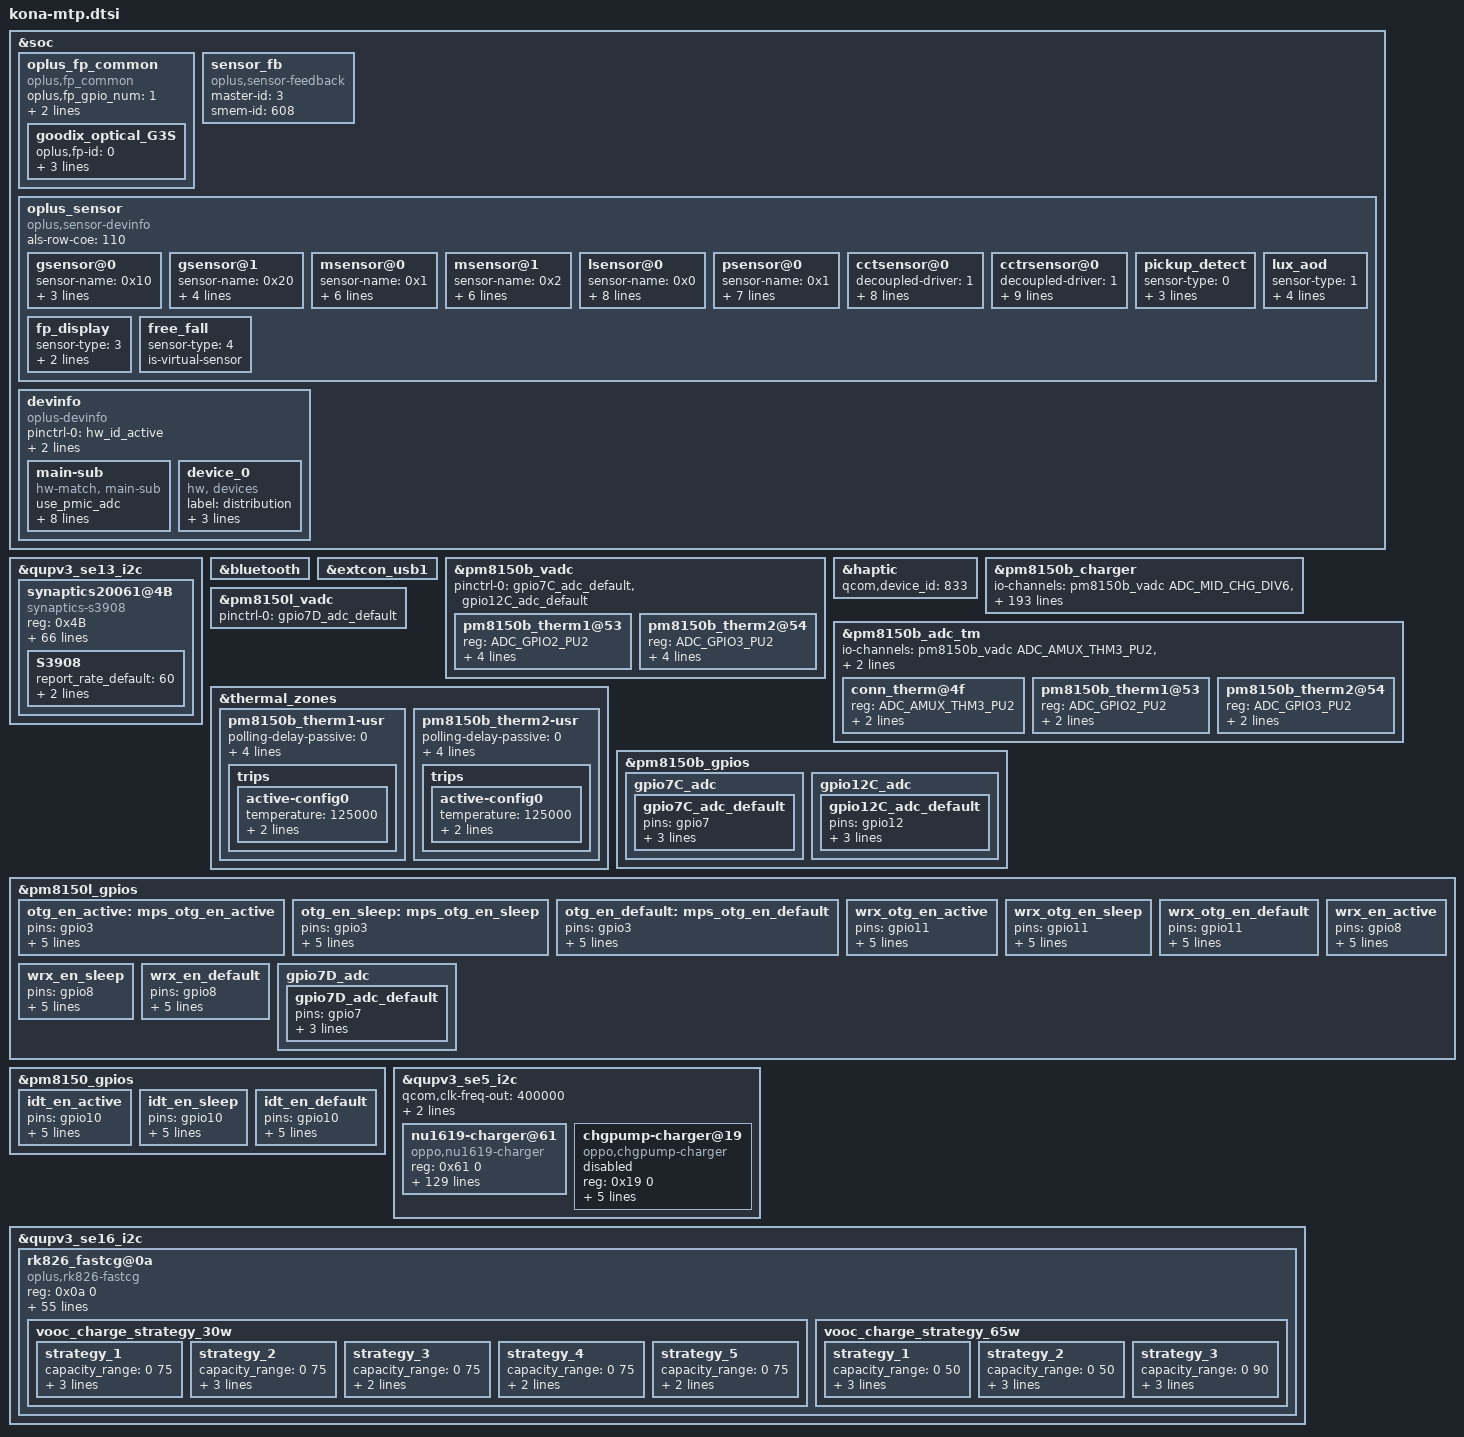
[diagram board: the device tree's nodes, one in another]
#include "kona-audio-overlay.dtsi"
#include "kona-camera-sensor-mtp-20061.dtsi"
#include "kona-pmic-overlay.dtsi"
#include "kona-sde-display.dtsi"

&soc {
	oplus_fp_common {
		compatible = "oplus,fp_common";
		oplus,fp_gpio_num = <1>; /* the gpio number of fingerprint id used */
		oplus,fp_gpio_0 = <&tlmm 9 0x0>;
				pinctrl-names = "default";
		pinctrl-0 = <&gpio_id2_default>;
		goodix_optical_G3S {
			oplus,fp-id = <0>; /* fp id mapping table */
			vendor-chip = <11>; /* please refer to the struct fp_vendor_t in oplus_fp_commmon.n */
			eng-menu = "-1,-1"; /* represents SNR, inclination test item in engineer menu, and 0/1 means off/on */
			chip-name = "G_OPTICAL_G3S";  /* /proc/fp_id, will be displayed in engineer menu  */
		};
	};

	/*enum sensor_id { ACCEL,GYRO,MAG,LIGHT,PROXIMITY,SAR,CT,BAROMETER,SENSORS_NUM};*/
    sensor_fb: sensor_fb {
        compatible = "oplus,sensor-feedback";
        master-id  = <3>;
        smem-id    = <608>;
    };

	oplus_sensor {
		compatible = "oplus,sensor-devinfo";
		als-row-coe = <110>;
		/*enum {LSM6DSM = 0x01, BMI160 = 0x02, LSM6DS3 = 0x04};*/
		gsensor@0 {
			sensor-name = <0x10>;//LSM6DSO
			sensor-direction = <7>;
			sensor-index = <0>;//source num
			sensor-type = <0>;//ACCEL
		};
		gsensor@1 {
			sensor-name = <0x20>;//ICM4X6XX
			sensor-direction = <7>;
			sensor-index = <1>;//source num
			sensor-type = <0>;//ACCEL
			use-sois = <1>;   //Use for TDK-sensor, <1>:S-OIS,  <0>:tele ois ic
		};
		/* enum {AKM0991X = 0x01, MMC5603 = 0x02};*/
		msensor@0 {
			sensor-name = <0x1>;//AKM0991X
			sensor-direction = <2>;
			sensor-index = <0>;
			sensor-type = <2>;//MAG
			parameter-number= <18>;
			//sensor-parameter = <2>;//0-useless;other- to differ special parameter
			soft-mag-parameter = <10000 0 0 0 0 0 0 0 10000 0 0 0 0 0 0 0 10000 0>;//e00 sign e01 sign ...
		};
		msensor@1 {
			sensor-name = <0x2>;//MMC5603
			sensor-direction = <1>;
			sensor-index = <1>;
			sensor-type = <2>;//MAG
			parameter-number= <18>;
			soft-mag-parameter = <9912 0 1306 0 174 0 914 0 9825 0 444 1 336 0 482 1 11899 0>;//e00 sign e01 sign ...

		};
		/*enum {STK3A5X=0x01,TCS3701=0x02,TCS3408=0x04};*/
		lsensor@0 {
			sensor-name = <0x0>;//TCS3408
			sensor-index = <0>;
			sensor-type = <3>;//LIGHT
			als-type = <1>;//<1-normal;2-under screen;3-normal needed compensation>
			is-unit-device = <0>;//<1-alsps unit device;0-separate device>
			is-als-dri = <0>;//<0-polling 1-irq>
			als-factor = <110>;
			is_als_initialed = <0>;
			als_buffer_length = <10>;
		};
		psensor@0 {
			sensor-name = <0x1>;//STK33502
			sensor-index = <0>;
			sensor-type = <4>;//PROXIMITY
			bus-number = <5>;
			irq-number = <129>;
			ps-type = <1>;
			parameter-number = <4>;
			sensor-reg = <0x01 0x31
					0xDB 0x00>;

		};
		/* enum {tcs3408 = 0x01  stk37600 = 0x02} */
		cctsensor@0 {
			decoupled-driver = <1>; //0 - tcs3408 driver; 1 - oplus_cct driver
			sensor-name = <0x1>; //tcs3408
			sensor-index = <0>;
			sensor-type = <6>; //CCT
			bus-number = <5>;
			publish-sensors = <0x7>; //bit[0] - als, bit[1] - rgb, bit[2] - flicker
			is-ch-dri = <0>;
			timer-size = <25>; //ms
			fac-cali-sensor = <0x2>; //0x1 - als, 0x2 - rgb, 0x4, flicker
		};
		cctrsensor@0 {
			decoupled-driver = <1>; //0 - tcs3408 driver; 1 - oplus_cct driver
			sensor-name = <0x1>; //tcs3408
			sensor-index = <0>;
			sensor-type = <7>; //CCT_REAR
			bus-number = <4>;
			publish-sensors = <0x7>; //bit[0] - als, bit[1] - rgb, bit[2] - flicker
			is-ch-dri = <0>;
			timer-size = <25>; //ms
			fac-cali-sensor = <0x2>; //0x1 - als, 0x2 - rgb, 0x4, flicker
			first-again = <32>;
		};
		/*virtual sensor
		enum sensor_algo_id {
			PICKUP_DETECT,
			LUX_AOD,
			TP_GESTURE,
			FP_DISPLAY,
			FREE_FALL,
			CAMERA_PROTECT,
			SENSOR_ALGO_NUM
		}*/
		pickup_detect {
			sensor-type = <0>;//PICKUP_DETECT
			is-virtual-sensor;
			is-need-prox = <1>;//0 - disable; 1 - enable
			prox-type = <0>;//prox_type: 0 - proximity; 1 - proximity_fake
		};
		lux_aod {
			sensor-type = <1>; //LUX_AOD
			is-virtual-sensor;
			thrd-low = <12>;
			thrd-high = <50>;
			als-type = <0>; // 0 - ambient_light; 1 - wise_light
		};
		fp_display {
			sensor-type = <3>;//FP_DISPLAY
			is-virtual-sensor;
			prox-type = <0>; //  0 - proximity; 1 - proximity_fake
		};
		free_fall {
			sensor-type = <4>;//FREE_FALL
			is-virtual-sensor;
		};
	};


	devinfo {
		compatible = "oplus-devinfo";

		pinctrl-names = "active", "sleep";
		pinctrl-0 = <&hw_id_active>;
		pinctrl-1 = <&hw_id_sleep>;

		io-channels= <&pm8150l_vadc ADC_GPIO1>;
		io-channel-names= "vph_pwr_voltage_sub";

		main-sub {
			compatible = "hw-match, main-sub";
			use_pmic_adc;
			adc_ranges = <0 80
						81 180
						181 300
						301 420
						421 550
						551 650
						651 760
						761 850
						851 950
						951 1050
						1051 1150
						1151 1300>;
			aboard-patterns = <1 1 1 1 1 1 1 1 1 1 1 1 1 1 1 1>;

			/*main board*/
			match-projects = <20061 20062 20061 20062 20061 20062
			                 20061 20062 20061 20062 20061 20062 20061 20062 20061 20062>;

			/*rf type*/
			rf_match_support;
			rf-patterns = <0 0 1 1 2 2 3 3 4 4 5 5 6 6 7 7>;
		};

		device_0 {
			compatible = "hw, devices";
			label = "distribution";
			hw-id0 = <&pm8150_gpios 1 0>;
			hw-combs = <1 0>;
			hw-names = "Standard", "Pro";
		};
	};
};

&qupv3_se13_i2c {
	status = "okay";

	synaptics20061@4B {
		compatible = "synaptics-s3908";
		reg = <0x4B>;
		chip-name = "S3908";

		/* Interrupt && Irq-gpio */
		interrupt-parent = <&tlmm>;
		interrupts = <39 0x2008>;

		/* Power Config */
		vdd_2v8-supply = <&pm8150_l13>;
		vcc_1v8-supply = <&pm8150a_l1>;
		vdd_2v8_volt = <3008000>;

		/* Other HW Resource */
		irq-gpio = <&tlmm 39 0x2008>;
		reset-gpio = <&tlmm 38 0x1>;
		pinctrl-names = "default";
		pinctrl-0 = <&ts_int_active &ts_reset_active>;

		vid_len = <0>;
		tp_type = <8>;
		// type of tp_dev ,TP-SAMSUNG = 8;
		platform_support_project = <20061 20062>;
		platform_support_project_dir = <20061 20061>;
		platform_support_project_commandline = "mdss_dsi_oplus20061_samsung_1440_3216", "mdss_dsi_oplus20061_samsung_1440_3216";

		touchpanel,max-num-support = <10>;
		touchpanel,tx-rx-num = <17 38>;
		touchpanel,panel-coords = <5760 12864>;
		touchpanel,display-coords = <1440 3216>;
		touchpanel,touchmajor-limit = <128 216>;
		touchpanel,int-mode = <1>; /*0: interrupt and disable, 1:interrupt and not disable*/
		touchpanel,curved-size = <45>;
		touchpanel,smooth-level = <0 2 3 4 10 13>;
		touchpanel,smooth-level-charging = <0 6 8 10 13 15>;
		touchpanel,sensitive-level = <0 88 70 64 45 20>;
		touchpanel,single-optimized-time = <8>;

		/*edge inhibition 3.0 Feature porting start*/
		prevention,curved_screen_V2;
		prevention,updelay_time_ms = <30>;
		prevention,makeup_cnt_weight = <4 1 2 2 2>;
		prevention,large_corner_range = <600 1400>;
		prevention,large_corner_judge_condition = <500 100 600 4 4>;
		prevention,trx_reject_condition = <8 7 7>;
		prevention,trx_strict_reject_condition = <8 5 5>;
		prevention,large_judge_time_ms = <500 50 40>;
		prevention,large_exit_condition = <8 8 2>;
		prevention,single_channel_width = <160 160>;
		prevention,normal_tap_condition = <10 300>;
		prevention,long_edge_condition = <230 90 180 80>;
		prevention,long_strict_edge_condition = <160 60>;
		prevention,long_fingerhold_condition = <50 6 4 4>;
		prevention,short_edge_condition = <200 90 180 80>;
		prevention,short_strict_edge_condition = <160 60>;
		prevention,large_strict_exit_condition = <2 2>;
		prevention,top_corner_config = <280 800 240>;
		prevention,edge_swipe_config = <150 400>;
                prevention,grip_disable_level = <6>;
		/*edg inhibition 3.0 Feature porting end*/

		/* SW Support Feature Control */
		health_monitor_v2_support;
		black_gesture_support;
		//fw_edge_limit_support;
		kernel_grip_support;
		pressure_report_support;
		charger_pump_support;
		game_switch_support;
		smart_gesture_support;
		fw_update_app_support;
		fingerprint_underscreen_support;
		freq_hop_simulate_support;
		report_flow_unlock_support;
		screenoff_fingerprint_info_support;
		irq_need_dev_resume_ok;
		black_gesture_indep_support;
		lcd_tp_refresh_support;
		/*
		 *Virtual Key Config:
		 *1:touchpanel,button-type: <virtualkey_type  supportted_button-map>
		 *virtualkey_type:
		 *Type 1: using board_properties
		 *Type 2: using same IC (button zone&& touch zone are seprate)
		 *Type 3: using diffrent IC (button zone&& touch zone are seprate)
		 *Type 4: No need of virtual key process
		 *supportted_button-map:select|menu|home|back
		 *
		 *2:touchpanel,button-map
		 *type (X1,Y1)(X2,Y2)(X3,Y3)(Width_X,Hight_Y)--Only when button-type is 0
		 */
		touchpanel,button-type = <4>;
		touchpanel.button-TRx = <0 0>;
		S3908 {
			report_rate_default = <60>;
			report_rate_game_value = <2>;
			fps_report_rate = <60 1 90 3 120 3>;//1:120hz 2:240hz 3: 180hz
		};
	};
};

&bluetooth {
	/delete-property/ qca,bt-vdd-dig-supply;
    /delete-property/ qca,bt-vdd-dig-voltage-level;
};

&extcon_usb1 {
	/delete-property/ id-gpio;
};

&pm8150b_vadc {
	pinctrl-names = "default";
	pinctrl-0 = <&gpio7C_adc_default &gpio12C_adc_default>;
	
	pm8150b_therm1@53 { //GPIO12
		reg = <ADC_GPIO2_PU2>;
		label = "pm8150b_therm1";
		qcom,ratiometric;
		qcom,hw-settle-time = <200>;
		qcom,pre-scaling = <1 1>;
	};
	
	pm8150b_therm2@54 { //GPIO7
		reg = <ADC_GPIO3_PU2>;
		label = "pm8150b_therm2";
		qcom,ratiometric;
		qcom,hw-settle-time = <200>;
		qcom,pre-scaling = <1 1>;
	};
};

&haptic {
    qcom,device_id = <833>;//20061
};

&pm8150b_charger {
	io-channels = <&pm8150b_vadc ADC_MID_CHG_DIV6>,
			  <&pm8150b_vadc ADC_USB_IN_I>,
			  <&pm8150b_vadc ADC_SBUx>,
			  <&pm8150b_vadc ADC_VPH_PWR>,
			  <&pm8150b_vadc ADC_CHG_TEMP>,
			  <&pm8150b_vadc ADC_AMUX_THM4_PU2>,
			  <&pm8150b_vadc ADC_GPIO4_PU2>;
	io-channel-names = "mid_voltage",
			   "usb_in_current",
			   "sbux_res",
			   "vph_voltage",
			   "chg_temp",
			   "usb_temp_adc",
			   "usb_supplementary_temp_adc";
};

&pm8150l_vadc {
	pinctrl-names = "default";
	pinctrl-0 = <&gpio7D_adc_default>;
};

&pm8150b_adc_tm {
    #address-cells = <1>;
    #size-cells = <0>;

    io-channels = <&pm8150b_vadc ADC_AMUX_THM3_PU2>,
                  <&pm8150b_vadc ADC_GPIO2_PU2>,
                  <&pm8150b_vadc ADC_GPIO3_PU2>;

    conn_therm@4f {
        reg = <ADC_AMUX_THM3_PU2>;
        qcom,ratiometric;
        qcom,hw-settle-time = <200>;
    };

    pm8150b_therm1@53 {   //GPIO12
        reg = <ADC_GPIO2_PU2>;
        qcom,ratiometric;
        qcom,hw-settle-time = <200>;
    };
 
    pm8150b_therm2@54 {  //GPIO7
        reg = <ADC_GPIO3_PU2>;
        qcom,ratiometric;
        qcom,hw-settle-time = <200>;
    };
};

&thermal_zones {
    pm8150b_therm1-usr {
        polling-delay-passive = <0>;
        polling-delay = <0>;
        thermal-governor = "user_space";
        thermal-sensors = <&pm8150b_adc_tm ADC_GPIO2_PU2>;
        wake-capable-sensor;
        trips {
            active-config0 {
                temperature = <125000>;
                hysteresis = <1000>;
                type = "passive";
            };
        };
    };
 
    pm8150b_therm2-usr {
        polling-delay-passive = <0>;
        polling-delay = <0>;
        thermal-governor = "user_space";
        thermal-sensors = <&pm8150b_adc_tm ADC_GPIO3_PU2>;
        wake-capable-sensor;
        trips {
            active-config0 {
                temperature = <125000>;
                hysteresis = <1000>;
                type = "passive";
            };
        };
    };
};

&pm8150b_gpios {
	gpio7C_adc {
		gpio7C_adc_default: gpio7C_adc_default {
			pins = "gpio7"; /* GPIO07 */
			function = "normal"; /* normal */
			bias-high-impedance; /* DISABLE GPIO07 for ADC*/
			bias-disable;
		};
	};
	
	gpio12C_adc {
		gpio12C_adc_default: gpio12C_adc_default {
			pins = "gpio12"; /* GPIO12 */
			function = "normal"; /* normal */
			bias-high-impedance; /* DISABLE GPIO12 for ADC*/
			bias-disable;
		};
	};
};

&pm8150l_gpios {
	otg_en_active: mps_otg_en_active {
		pins = "gpio3"; /* GPIO 3 */
		function = "normal"; /* normal */
		bias-disable; //No Pull
		power-source = <0>;//VIN1 1.8
		output-high; //digital output, no invert
		qcom,drive-strength = <3>; //LOW strength
		//drive-push-pull;//CMOS
	};

	otg_en_sleep: mps_otg_en_sleep {
		pins = "gpio3"; /* GPIO 3 */
		function = "normal"; /* normal */
		bias-disable; //No Pull
		power-source = <0>;//VIN1 1.8
		output-low; //digital output, no invert
		qcom,drive-strength = <3>; //LOW strength
		//drive-push-pull;//CMOS
	};

	otg_en_default: mps_otg_en_default {
		pins = "gpio3"; /* GPIO 3 */
		function = "normal"; /* normal */
		bias-disable; //No Pull
		power-source = <0>;//VIN1 1.8
		output-low; //digital output, no invert
		qcom,drive-strength = <3>; //LOW strength
		//drive-push-pull;//CMOS
	};
};


&pm8150_gpios {
	idt_en_active: idt_en_active {
		pins = "gpio10"; /* GPIO 10 */
		function = "normal"; /* normal */
		bias-disable; //No Pull
		power-source = <1>;//VIN1 1.8
		output-high; //digital output, no invert
		qcom,drive-strength = <3>; //LOW strength
		//drive-push-pull;//CMOS
	};
	idt_en_sleep: idt_en_sleep {
		pins = "gpio10"; /* GPIO 10 */
		function = "normal"; /* normal */
		bias-disable; //No Pull
		power-source = <1>;//VIN1 1.8
		output-low; //digital output, no invert
		qcom,drive-strength = <3>; //LOW strength
		//drive-push-pull;//CMOS
	};
	idt_en_default: idt_en_default {
		pins = "gpio10"; /* GPIO 10 */
		function = "normal"; /* normal */
		bias-disable; //No Pull
		power-source = <1>;//VIN1 1.8
		output-low; //digital output, no invert
		qcom,drive-strength = <3>; //LOW strength
		//drive-push-pull;//CMOS
	};
};


&pm8150l_gpios {	
	wrx_otg_en_active: wrx_otg_en_active {
		pins = "gpio11"; /* GPIO 11 */
		function = "normal"; /* normal */
		bias-disable; //No Pull
		power-source = <1>;//VIN1 1.8
		output-high; //digital output, no invert
		qcom,drive-strength = <3>; //LOW strength
		//drive-push-pull;//CMOS
	};

	wrx_otg_en_sleep: wrx_otg_en_sleep {
		pins = "gpio11"; /* GPIO 11 */
		function = "normal"; /* normal */
		bias-disable; //No Pull
		power-source = <1>;//VIN1 1.8
		output-low; //digital output, no invert
		qcom,drive-strength = <3>; //LOW strength
		//drive-push-pull;//CMOS
	};

	wrx_otg_en_default: wrx_otg_en_default {
		pins = "gpio11"; /* GPIO 11 */
		function = "normal"; /* normal */
		bias-disable; //No Pull
		power-source = <1>;//VIN1 1.8
		input-enable; //digital output, no invert
		qcom,drive-strength = <3>; //LOW strength
		//drive-push-pull;//CMOS
	};

	wrx_en_active: wrx_en_active {
		pins = "gpio8"; /* GPIO 11 */
		function = "normal"; /* normal */
		bias-disable; //No Pull
		power-source = <1>;//VIN1 1.8
		output-high; //digital output, no invert
		qcom,drive-strength = <3>; //LOW strength
		//drive-push-pull;//CMOS
	};

	wrx_en_sleep: wrx_en_sleep {
		pins = "gpio8"; /* GPIO 11 */
		function = "normal"; /* normal */
		bias-disable; //No Pull
		power-source = <1>;//VIN1 1.8
		output-low; //digital output, no invert
		qcom,drive-strength = <3>; //LOW strength
		//drive-push-pull;//CMOS
	};

	wrx_en_default: wrx_en_default {
		pins = "gpio8"; /* GPIO 11 */
		function = "normal"; /* normal */
		bias-disable; //No Pull
		power-source = <1>;//VIN1 1.8
		input-enable; //digital input, no invert
		qcom,drive-strength = <3>; //LOW strength
		//drive-push-pull;//CMOS
	};
};

&pm8150l_gpios {
	gpio7D_adc {
		gpio7D_adc_default: gpio7D_adc_default {
			pins = "gpio7"; /* GPIO07 */
			function = "normal"; /* normal */
			bias-high-impedance; /* DISABLE GPIO07 for ADC*/
			bias-disable;
		};
	};
};

&qupv3_se5_i2c {
	status = "okay";
	qcom,clk-freq-out = <400000>;
	qcom,noise-rjct-scl = <3>;
	qcom,noise-rjct-sda = <3>;

	nu1619-charger@61 {    //sp6001
		status = "okay";
		compatible = "oppo,nu1619-charger";
		reg = <0x61 0>;	   //sp6001

		qcom,bpp_input_ma = <750>;
		qcom,epp_input_ma = <800>;
		qcom,epp_input_step_ma = <100>;
		qcom,vooc_input_ma = <1000>;
		qcom,vooc_iout_ma = <1000>;
		qcom,svooc_input_ma = <1000>;
		qcom,svooc_65w_iout_ma = <2300>;
		qcom,svooc_50w_iout_ma = <1750>;

		qcom,bpp_temp_cold_fastchg_ma = <300>;						// -2

		qcom,vooc_temp_little_cold_fastchg_ma = <1200>;		// 0
		qcom,svooc_temp_little_cold_iout_ma = <650>;
		qcom,svooc_temp_little_cold_fastchg_ma = <1200>;
		qcom,bpp_temp_little_cold_fastchg_ma = <600>;
		qcom,epp_temp_little_cold_fastchg_ma = <1400>;

		qcom,vooc_temp_cool_fastchg_ma = <1200>;				// 5
		qcom,svooc_temp_cool_iout_ma = <650>;
		qcom,svooc_temp_cool_fastchg_ma = <1200>;
		qcom,bpp_temp_cool_fastchg_ma = <600>;
		qcom,epp_temp_cool_fastchg_ma = <1400>;

		qcom,vooc_temp_little_cool_fastchg_ma = <1200>;		// 12
		qcom,svooc_temp_little_cool_fastchg_ma = <1200>;
		qcom,bpp_temp_little_cool_fastchg_ma = <600>;
		qcom,epp_temp_little_cool_fastchg_ma = <1400>;

		qcom,vooc_temp_normal_fastchg_ma = <1200>;		// 16
		qcom,svooc_temp_normal_fastchg_ma = <1200>;
		qcom,bpp_temp_normal_fastchg_ma = <600>;
		qcom,epp_temp_normal_fastchg_ma = <1400>;

		qcom,vooc_temp_warm_fastchg_ma = <3000>;		// 45
		qcom,svooc_temp_warm_fastchg_ma = <1200>;
		qcom,bpp_temp_warm_fastchg_ma = <600>;
		qcom,epp_temp_warm_fastchg_ma = <1200>;

		qcom,curr_cp_to_charger = <400>;
		qcom,support_airsvooc = <1>;

		qcom,wireless_max_chg_vol_mv = <15000>;
		qcom,wireless_max_chg_current_ma = <3600>;
		qcom,wireless_chg_current_index = <1>;

		qcom,svooc_target_ichg_cold_fastchg_ma = <500>;              // -2

		qcom,svooc_target_ichg_little_cold_fastchg_ma = <1500>;      // 0
		qcom,vooc_target_ichg_little_cold_fastchg_ma = <1200>;
		qcom,bpp_target_ichg_little_cold_fastchg_ma = <500>;
		qcom,epp1_target_ichg_little_cold_fastchg_ma = <500>;      //EPP8W
		qcom,epp2_target_ichg_little_cold_fastchg_ma = <1000>;      //EPP10W
		qcom,epp3_target_ichg_little_cold_fastchg_ma = <1500>;      //EPP15W

		qcom,svooc_target_ichg_cool_fastchg_ma = <2000>;      //5
		qcom,vooc_target_ichg_cool_fastchg_ma = <1200>;
		qcom,bpp_target_ichg_cool_fastchg_ma = <500>;
		qcom,epp1_target_ichg_cool_fastchg_ma = <500>;      //EPP8W
		qcom,epp2_target_ichg_cool_fastchg_ma = <1000>;      //EPP10W
		qcom,epp3_target_ichg_cool_fastchg_ma = <1500>;      //EPP15W

		qcom,svooc_target_ichg_normal_region1_fastchg_ma = <3000>;      //12
		qcom,vooc_target_ichg_normal_region1_fastchg_ma = <1200>;
		qcom,bpp_target_ichg_normal_region1_fastchg_ma = <500>;
		qcom,epp1_target_ichg_normal_region1_fastchg_ma = <500>;      //EPP8W
		qcom,epp2_target_ichg_normal_region1_fastchg_ma = <1000>;      //EPP10W
		qcom,epp3_target_ichg_normal_region1_fastchg_ma = <1500>;      //EPP15W

		qcom,svooc_target_ichg_normal_region2_fastchg_ma = <1500>;      //37.5
		qcom,vooc_target_ichg_normal_region2_fastchg_ma = <1200>;
		qcom,bpp_target_ichg_normal_region2_fastchg_ma = <500>;
		qcom,epp1_target_ichg_normal_region2_fastchg_ma = <500>;      //EPP8W
		qcom,epp2_target_ichg_normal_region2_fastchg_ma = <1000>;      //EPP10W
		qcom,epp3_target_ichg_normal_region2_fastchg_ma = <1000>;      //EPP15W

		qcom,svooc_target_ichg_normal_region3_fastchg_ma = <1200>;      //40
		qcom,vooc_target_ichg_normal_region3_fastchg_ma = <500>;
		qcom,bpp_target_ichg_normal_region3_fastchg_ma = <500>;
		qcom,epp_target_ichg_normal_region3_fastchg_ma = <500>;

		qcom,svooc_target_ichg_warm_fastchg_ma = <500>;      //45
		qcom,wireless_power = <30>;

		ffc_target_ichg_table = <5000 3000 1850     //vbatt,target_ichg,input_current
								 5000 2500 1550
								 5000 2000 1250
								 5000 1500 950
								 5000 1200 950
								 5000 1000 800
								 5000 700 700
								 5000 550 500
								 5000 500 400
								 5000 350 400
								 0 0 0>;

		svooc_target_ichg_table = <3700 3000 1600     //vbatt,target_ichg,input_current
								   3700 2500 1350
								   3700 2000 1100
								   3700 1500 850
								   3900 3000 1700
								   3900 2500 1450
								   3900 2000 1200
								   3900 1500 900
								   4100 3000 1800
								   4100 2500 1500
								   4100 2000 1200
								   4100 1500 900
								   5000 3000 1850
								   5000 2500 1550
								   5000 2000 1250
								   5000 1500 950
								   5000 1200 950
								   5000 500 400
								   5000 400 300
								   0 0 0>;

		vooc_target_ichg_table = <5000 1200 950     //vbatt,target_ichg,input_current
								  5000 500 400
								  5000 400 300
								  5000 200 400
								  0 0 0>;

		epp_target_ichg_table = <5000 1500 1200     //vbatt,target_ichg,input_current
								 5000 1000 800
								 5000 500 400
								 5000 400 300
								 0 0 0>;

		bpp_target_ichg_table = <5000 500 750     //vbatt,target_ichg,input_current
								 5000 200 400
								 0 0 0>;

		fasctchg_current_level = <0			/*FASTCHARGE_LEVEL_UNKNOW*/
							3000		/*FASTCHARGE_LEVEL_1*/
							2500		/*FASTCHARGE_LEVEL_2*/
							2000		/*FASTCHARGE_LEVEL_3*/
							1500		/*FASTCHARGE_LEVEL_4*/
							1200		/*FASTCHARGE_LEVEL_5*/
							1000		/*FASTCHARGE_LEVEL_6*/
							700		    /*FASTCHARGE_LEVEL_7*/
							550		    /*FASTCHARGE_LEVEL_8*/
							500		    /*FASTCHARGE_LEVEL_9*/
							350>;	    /*FASTCHARGE_LEVEL_10*/
		ffc_max_vol_level = <0 4300 4330 4360 4390 4400 0 4460 4445 0 4440>;  /*LEVEL1~10*/
		non_ffc_max_vol_level = <0 4230 4260 4290 4320 4340 4350 0 0 4400>;   /*LEVEL1~9*/

		pinctrl-names = "idt_int_active", "idt_int_sleep", "idt_int_default",
						"idt_connect_active", "idt_connect_sleep", "idt_connect_default",
						"vbat_en_active", "vbat_en_sleep", "vbat_en_default",
						"vt_sleep_active", "vt_sleep_sleep", "vt_sleep_default",
						"wrx_en_active", "wrx_en_sleep", "wrx_en_default",
						"wrx_otg_en_active", "wrx_otg_en_sleep", "wrx_otg_en_default";
						//"booster_en_active", "booster_en_sleep", "booster_en_default",
						//"ext2_wireless_otg_en_active", "ext2_wireless_otg_en_sleep", "ext2_wireless_otg_en_default",
						//"ext1_wired_otg_en_active","ext1_wired_otg_en_sleep","ext1_wired_otg_en_default",
						//"cp_ldo_5v_active","cp_ldo_5v_sleep","cp_ldo_5v_default";

		pinctrl-0 = <&idt_int_active>;
		pinctrl-1 = <&idt_int_sleep>;
		pinctrl-2 = <&idt_int_default>;
		pinctrl-3 = <&idt_connect_active>;
		pinctrl-4 = <&idt_connect_sleep>;
		pinctrl-5 = <&idt_connect_default>;
		pinctrl-6 = <&vbat_en_active>;
		pinctrl-7 = <&vbat_en_sleep>;
		pinctrl-8 = <&vbat_en_default>;
		pinctrl-9 = <&vt_sleep_active>;
		pinctrl-10 = <&vt_sleep_sleep>;
		pinctrl-11 = <&vt_sleep_default>;
		pinctrl-12 = <&wrx_en_active>;
		pinctrl-13 = <&wrx_en_sleep>;
		pinctrl-14 = <&wrx_en_default>;
		pinctrl-15 = <&wrx_otg_en_active>;
		pinctrl-16 = <&wrx_otg_en_sleep>;
		pinctrl-17 = <&wrx_otg_en_default>;

		qcom,idt_int-gpio = <&tlmm 118 0x00>;
		qcom,idt_connect-gpio = <&tlmm 113 0x00>;
		qcom,vbat_en-gpio = <&tlmm 117 0x00>;
		qcom,vt_sleep-gpio = <&tlmm 119 0x00>;
		qcom,wrx_en-gpio = <&pm8150l_gpios 8 0x00>;
		qcom,wrx_otg_en-gpio = <&pm8150l_gpios 11 0x00>;
	};

	chgpump-charger@19 {	//OP20A
		status = "disabled";
		compatible = "oppo,chgpump-charger";
		reg = <0x19 0>;		//OP20A
		
		qcom,cp_en-gpio = <&tlmm 114 0x00>;
		qcom,cp_int-gpio = <&tlmm 126 0x00>; // irq gpio
		pinctrl-names = "cp_en_active", "cp_en_sleep", "cp_en_default";
		pinctrl-0 = <&cp_en_active>;
		pinctrl-1 = <&cp_en_sleep>;
		pinctrl-2 = <&cp_en_default>;
	};
};
#include "opluschg_wireless_fw.dtsi"

&qupv3_se16_i2c {
	rk826_fastcg@0a{
		status = "okay";
		compatible = "oplus,rk826-fastcg";
		reg = <0x0a 0>;
		qcom,vooc-low-temp = <0>;
		qcom,oplus_batt_4400mv;
		qcom,support_vooc_by_normal_charger_path;
		qcom,vooc_fw_update_newmethod;
		qcom,vooc-high-temp = <500>;
		qcom,vooc-low-soc = <1>;
		qcom,vooc-high-soc = <90>;
		qcom,vooc-fw-type = <5>;
		qcom,vooc_reply_mcu_bits = <7>;
		qcom,vooc-version = <5>;

		qcom,vooc-normal-high-temp = <430>;
		qcom,vooc-warm-allow-vol = <4130>;
		qcom,vooc-warm-allow-soc = <50>;

		qcom,vooc_multistep_adjust_current_support;
		qcom,vooc_multistep_initial_batt_temp = <1000>;
		qcom,vooc_strategy_normal_current = <0x0C>;
		qcom,vooc_batt_over_high_temp = <510>;

		qcom,vooc_strategy1_batt_high_temp0 = <400>;
		qcom,vooc_strategy1_batt_high_temp1 = <420>;
		qcom,vooc_strategy1_batt_high_temp2 = <430>;
		qcom,vooc_strategy1_batt_low_temp2 = <420>;
		qcom,vooc_strategy1_batt_low_temp1 = <410>;
		qcom,vooc_strategy1_batt_low_temp0 = <390>;

		qcom,vooc_strategy1_high_current0 = <0x09>;
		qcom,vooc_strategy1_high_current1 = <0x07>;
		qcom,vooc_strategy1_high_current2 = <0x5>;
		qcom,vooc_strategy1_low_current2 = <0x07>;
		qcom,vooc_strategy1_low_current1 = <0x09>;
		qcom,vooc_strategy1_low_current0 = <0x0C>;
		qcom,vooc_current_lvl = <1000
					1500
					2000
					2500
					3000
					3500
					4000
					4500
					5000
					5500
					6000
					6500
					7000
					7500
					8000
					8500
					9000
					9500
					10000
					10500
					11000
					11500
					12000
					12500>;

		qcom,abnormal_adapter_current = <0x00 0x00 0x09 0x09 0x07 0x07 0x05 0x05 0x03 0x03>;

		pinctrl-names = "switch1_act_switch2_act", "switch1_sleep_switch2_sleep",
						"switch1_act_switch3_act", "switch1_sleep_switch3_sleep",
						"switch1_act_switch2_sleep", "switch1_sleep_switch2_act",
						"clock_active","clock_sleep",
						"data_active","data_sleep",
						"reset_active","reset_sleep",
						"vooc_asic_id_active","vooc_asic_id_sleep";
//						"charging_switch1_ctr1_active","charging_switch1_ctr1_sleep";
		pinctrl-0 = <&charging_switch1_active>;
		pinctrl-1 = <&charging_switch1_sleep>;
		pinctrl-2 = <&charging_switch1_active>;
		pinctrl-3 = <&charging_switch1_sleep>;
		pinctrl-4 = <&charging_switch1_active>;
		pinctrl-5 = <&charging_switch1_sleep>;
		pinctrl-6 = <&charging_clock_active>;
		pinctrl-7 = <&charging_clock_sleep>;
		pinctrl-8 = <&charging_data_active>;
		pinctrl-9 = <&charging_data_sleep>;
		pinctrl-10 = <&charging_reset_active>;
		pinctrl-11 = <&charging_reset_sleep>;
//		pinctrl-12 = <&charging_switch1_ctr1_active>;
//		pinctrl-13 = <&charging_switch1_ctr1_sleep>;
		pinctrl-12 = <&vooc_asic_id_active>;
		pinctrl-13 = <&vooc_asic_id_sleep>;


		qcom,charging_switch1-gpio 		= <&tlmm 82 0x00>;		//check
		qcom,charging_switch1_ctr1-gpio 	= <&tlmm 120 0x00>;	//empty
		//qcom,charging_switch2-gpio 		= <&tlmm 113 0x00>;
		//qcom,charging_switch3-gpio 		= <&tlmm 38 0x00>;

		qcom,charging_reset-gpio 		= <&tlmm 10 0x00>;		//check
		qcom,charging_clock-gpio 		= <&tlmm 121 0x00>;		//check
		qcom,charging_data-gpio 		= <&tlmm 122 0x00>;		//check
		qcom,vooc_asic_id-gpio			= <&tlmm 64 0x00>;

		qcom,vooc-max-input-volt-support = <10000>;     //10V
		qcom,vooc-max-input-current-support = <6500>;   //6A
		vooc_charge_strategy_30w {
			strategy_1 {
				capacity_range = <0 75>;
				temp_range = <120 160>;
				input_current = <4000 4450 0
						3000 4470 0
						2000 4480 0>;
			};
			strategy_2 {
				capacity_range = <0 75>;
				temp_range = <160 410>;
				input_current = <6000 4200 900
						5000 4200 0
						4500 4450 0
						4000 4450 0
						3000 4470 0
						2000 4480 0>;
			};
			strategy_3 {
				capacity_range = <0 75>;
				temp_range = <410 420>;
				input_current = <4000 4470 0
						2000 4480 0>;
			};
			strategy_4 {
				capacity_range = <0 75>;
				temp_range = <420 425>;
				input_current = <4000 4480 0>;
			};
			strategy_5 {
				capacity_range = <0 75>;
				temp_range = <425 435>;
				input_current = <3000 4480 0>;
			};
		};

		vooc_charge_strategy_65w {
			strategy_1 {
				capacity_range = <0 50>;
				temp_range = <120 160>;
				input_current = <5000 4184 0
						4500 4184 0
						4000 4454 0
						3500 4454 0
						3000 4454 0
						2000 4484 0
						1500 4484 0>;
			};
			strategy_2 {
				capacity_range = <0 50>;
				temp_range = <160 370>;
				input_current = <6500 4224 0
						6000 4224 0
						5500 4224 300
						5000 4224 0
						4500 4224 0
						4000 4454 0
						3500 4454 0
						2000 4484 0
						1500 4484 0>;
			};
			strategy_3 {
				capacity_range = <0 90>;
				temp_range = <370 430>;
				input_current = <6500 4224 0
						6000 4224 0
						5500 4224 300
						5000 4224 0
						4500 4224 0
						4000 4454 0
						3500 4454 0
						2000 4484 0
						1500 4484 0>;
			};
		};
	};
};

&pm8150b_charger {
    qcom,smart_charging_screenoff;
    //for oplus chg framework:
    qcom,input_current_charger_ma = <2000>;
    qcom,pd_input_current_charger_ma = <2000>;
    qcom,qc_input_current_charger_ma = <2000>;

    qcom,input_current_usb_ma = <500>;

			qcom,input_current_cdp_ma = <1500>;
			qcom,input_current_led_ma = <1200>;
			qcom,input_current_led_ma_high = <1800>;
			qcom,input_current_led_ma_warm = <1800>;
			qcom,input_current_led_ma_normal = <2000>;
			qcom,led_warm_bat_decidegc = <350>;
			qcom,led_high_bat_decidegc = <370>;

			qcom,input_current_camera_ma = <1200>;

			qcom,input_current_vooc_led_ma_high = <1200>;
			qcom,input_current_vooc_led_ma_warm = <1800>;
			qcom,input_current_vooc_led_ma_normal = <3600>;
			qcom,input_current_vooc_ma_normal = <3600>;
			qcom,vooc_temp_bat_normal_decidegc = <350>;
			qcom,input_current_vooc_ma_warm = <3200>;
			qcom,vooc_temp_bat_warm_decidegc = <370>;
			qcom,input_current_vooc_ma_high = <2200>;
			qcom,vooc_temp_bat_hot_decidegc = <510>;

			qcom,charger_current_vooc_ma_normal = <1800>;

			qcom,chg_ctrl_by_calling;
			qcom,input_current_calling_ma = <1500>;

			//qcom,input_current_led_ma_overtemp = <900>;
			qcom,overtemp_bat_decidegc = <350>;
			qcom,iterm_disabled = <0>;
			qcom,iterm_ma = <120>;
			qcom,recharge-mv = <100>;
			qcom,batt_capacity_mah = <4500>;/*typical capacity*/
			//qcom,batt_capacity_mah = <4400>; /*rated capacity*/

			qcom,removed_bat_decidegc = <190>;  /*<-19C*/

			qcom,cold_bat_decidegc = <20>;  /*-2C~0C*/
			qcom,temp_cold_vfloat_mv = <3980>;
			qcom,temp_cold_fastchg_current_ma = <300>;

			qcom,little_cold_bat_decidegc = <0>;	/*0C~5C*/
			qcom,temp_little_cold_vfloat_mv = <4435>;
			qcom,temp_little_cold_fastchg_current_ma_high = <1100>;
			qcom,temp_little_cold_fastchg_current_ma_low = <1100>;
			qcom,temp_little_cold_fastchg_current_ma = <1100>;
			qcom,pd_temp_little_cold_fastchg_current_ma_high = <2000>;
			qcom,pd_temp_little_cold_fastchg_current_ma_low = <1450>;
			qcom,qc_temp_little_cold_fastchg_current_ma_high = <2000>;
			qcom,qc_temp_little_cold_fastchg_current_ma_low = <1450>;

			qcom,cool_bat_decidegc = <50>;	/*5C~12C*/
			qcom,temp_cool_vfloat_mv = <4435>;
			qcom,temp_cool_fastchg_current_ma_high = <1100>;
			qcom,temp_cool_fastchg_current_ma_low = <1100>;
			qcom,pd_temp_cool_fastchg_current_ma_high = <2000>;
			qcom,pd_temp_cool_fastchg_current_ma_low = <2000>;
			qcom,qc_temp_cool_fastchg_current_ma_high = <2000>;
			qcom,qc_temp_cool_fastchg_current_ma_low = <2000>;

			qcom,little_cool_bat_decidegc = <120>;	/*12C~16C*/
			qcom,temp_little_cool_vfloat_mv = <4435>;
			qcom,temp_little_cool_fastchg_current_ma = <1100>;
			qcom,pd_temp_little_cool_fastchg_current_ma = <2000>;
			qcom,qc_temp_little_cool_fastchg_current_ma = <2000>;

			qcom,normal_bat_decidegc = <160>;	/*16C~44C*/
			qcom,temp_normal_fastchg_current_ma = <1100>;
			qcom,temp_normal_vfloat_mv = <4435>;
			qcom,pd_temp_normal_fastchg_current_ma = <2000>;
			qcom,qc_temp_normal_fastchg_current_ma = <2000>;

			qcom,warm_bat_decidegc = <450>;		/*45C~53C*/ /*8pin Bat Vooc project need add 3 degree C*/
			qcom,temp_warm_vfloat_mv = <4130>;
			qcom,temp_warm_fastchg_current_ma = <600>;
			qcom,pd_temp_warm_fastchg_current_ma = <600>;
			qcom,qc_temp_warm_fastchg_current_ma = <600>;
			qcom,temp_warm_fastchg_current_ma_led_on = <250>;

			qcom,hot_bat_decidegc = <530>;

			qcom,non_standard_vfloat_mv = <3980>;
			qcom,non_standard_fastchg_current_ma = <512>;

			qcom,short_c_bat_cv_mv = <4330>;
			qcom,short_c_bat_vfloat_mv = <3800>;
			qcom,short_c_bat_fastchg_current_ma = <512>;

			qcom,cold_vfloat_sw_limit = <3930>;
			qcom,little_cold_vfloat_sw_limit = <4385>;
			qcom,cool_vfloat_sw_limit = <4385>;
			qcom,little_cool_vfloat_sw_limit = <4385>;
			qcom,normal_vfloat_sw_limit = <4385>;
			qcom,warm_vfloat_sw_limit = <4080>;
			qcom,non_standard_vfloat_sw_limit = <3930>;
			qcom,short_c_bat_vfloat_sw_limit = <3750>;

			qcom,max_chg_time_sec = <36000>;
			qcom,charger_hv_thr = <9900>;
			qcom,charger_recv_thr = <9500>;
			qcom,charger_lv_thr = <3400>;
			qcom,vbatt_full_thr = <4435>;
			qcom,vbatt_hv_thr = <4600>;
			qcom,vfloat_step_mv = <8>;
			qcom,non_standard_vfloat_over_sw_limit = <3990>;
			qcom,cold_vfloat_over_sw_limit = <3990>;
			qcom,little_cold_vfloat_over_sw_limit = <4445>;
			qcom,cool_vfloat_over_sw_limit = <4445>;
			qcom,little_cool_vfloat_over_sw_limit = <4445>;
			qcom,normal_vfloat_over_sw_limit = <4445>;
			qcom,warm_vfloat_over_sw_limit = <4140>;

			qcom,vbatt_power_off = <3300>;
			qcom,vbatt_soc_1 = <3310>;
			qcom,vooc_project = <3>;
			qcom,vbatt_num = <2>;
			qcom,ffc_support;
			qcom,dual_ffc;
			recharge_after_full;
			qcom,wireless_support;
			qcom,wpc_no_chargerpump;

			qcom,normal_vterm_hw_inc = <18>;
			qcom,non_normal_vterm_hw_inc = <18>;

			qcom,ff1_normal_fastchg_ma = <550>;
			qcom,ff1_warm_fastchg_ma = <550>;
			qcom,ffc2_normal_fastchg_ma = <350>;/*12C~35c*/
			qcom,ffc2_temp_warm_decidegc = <350>;
			qcom,ffc2_warm_fastchg_ma = <400>;/*35C~40c*/
			qcom,ffc2_temp_high_decidegc = <400>;
			qcom,ffc2_temp_low_decidegc = <120>;
			qcom,ffc2_exit_step_ma = <150>;
			qcom,ff1_exit_step_ma = <150>;
			qcom,ff1_warm_exit_step_ma = <150>;

			qcom,ffc_normal_vfloat_sw_limit = <4445>;
			qcom,ffc2_normal_vfloat_sw_limit = <4440>;
			qcom,ffc2_warm_vfloat_sw_limit = <4440>;
			qcom,ffc_temp_normal_vfloat_mv = <4500>;
			qcom,ffc1_temp_normal_vfloat_mv = <4500>;
			qcom,ffc2_temp_normal_vfloat_mv = <4500>;
			qcom,ffc_normal_vfloat_over_sw_limit = <4500>;
			qcom,ffc1_normal_vfloat_over_sw_limit = <4500>;
			qcom,ffc2_normal_vfloat_over_sw_limit = <4500>;

			qcom,default_iterm_ma = <120>;
			qcom,default_temp_normal_fastchg_current_ma = <1100>;
			qcom,default_normal_vfloat_sw_limit = <4385>;
			qcom,default_temp_normal_vfloat_mv = <4435>;
			qcom,default_normal_vfloat_over_sw_limit = <4445>;

			qcom,default_temp_little_cool_fastchg_current_ma = <1100>;
			qcom,default_little_cool_vfloat_sw_limit = <4385>;
			qcom,default_temp_little_cool_vfloat_mv = <4435>;
			qcom,default_little_cool_vfloat_over_sw_limit = <4445>;

			///qcom,offset_temp = <30>;
			//for control:
			//qcom,suspend_after_full;
			qcom,check_batt_full_by_sw;
			qcom,external_gauge;
			qcom,chg_ctrl_by_lcd;
			qcom,chg_ctrl_by_vooc;
			qcom,chg_ctrl_by_camera;
			qcom,sw_vfloat_over_protect_enable;
			qcom,flash_screen_ctrl_dtsi;
			qcom,lpd-disable;

			qcom,support_abnormal_adapter;

			//for PD9V or QC9V
			qcom,vbatt_pdqc_to_5v_thr = <4100>;

			qcom,vooc_show_ui_soc_decimal;
			qcom,ui_soc_decimal_speedmin = <20>;//2A

			qcom,support_low_soc_unlimit;
			qcom,unlimit_soc = <35>;

			qcom,chargerid_switch-gpio = <&tlmm 50 0x00>;
			qcom,ship-gpio = <&tlmm 22 0x00>;
			qcom,ccdetect-gpio = <&tlmm 14 0x00>;
			//qcom,shortc-gpio = <&tlmm 43 0x00>;
			qcom,dischg-gpio = <&pm8150_gpios 9 0x00>;
			//qcom,charger_int-gpio = <&tlmm 15 0x00>;
			//qcom,input_pg-gpio = <&tlmm 6 0x00>;
			//qcom,charger_error-gpio = <&tlmm 118 0x00>;

			////qcom,wired_conn-gpio = <&pm8150_gpios 1 0x00>;///
			qcom,otg_en-gpio = <&pm8150l_gpios 3 0x00>;  /// ???
			//qcom,idt_en-gpio = <&pm8150_gpios 10 0x00>;

			pinctrl-names = "charger_error_default",
							"chargerid_switch_active", "chargerid_switch_sleep", "chargerid_switch_default",
							"ship_active", "ship_sleep",
							"ccdetect_active", "ccdetect_sleep",
							"dischg_enable", "dischg_disable",
							"gpio1_adc_default","gpio8_adc_default","gpio5_adc_default",
							"charger_int_default",
							"input_pg_default",

							"idt_en_active", "idt_en_sleep", "idt_en_default",
							"otg_en_active", "otg_en_sleep", "otg_en_default";
							//"wired_con_int_active","wired_con_int_sleep";


			pinctrl-0 = <&charger_error_default>;
			pinctrl-1 = <&chargerid_switch_active>;
			pinctrl-2 = <&chargerid_switch_sleep>;
			pinctrl-3 = <&chargerid_switch_default>;
			pinctrl-4 = <&ship_active>;
			pinctrl-5 = <&ship_sleep>;
			pinctrl-6 = <&ccdetect_active>;
			pinctrl-7 = <&ccdetect_sleep>;
			pinctrl-8 = <&dischg_enable>;
			pinctrl-9 = <&dischg_disable>;
			pinctrl-10 = <&gpio1_adc_default>;
			pinctrl-11 = <&gpio8_adc_default>;
			pinctrl-12 = <&gpio5_adc_default>;
			pinctrl-13 = <&charger_int_default>;
			pinctrl-14 = <&input_pg_default>;

			pinctrl-15 = <&idt_en_active>;
			pinctrl-16 = <&idt_en_sleep>;
			pinctrl-17 = <&idt_en_default>;
			pinctrl-18 = <&otg_en_active>;
			pinctrl-19 = <&otg_en_sleep>;
			pinctrl-20 = <&otg_en_default>;
			//pinctrl-27 = <&wired_con_int_active>;
			//pinctrl-28 = <&wired_con_int_sleep>;
};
